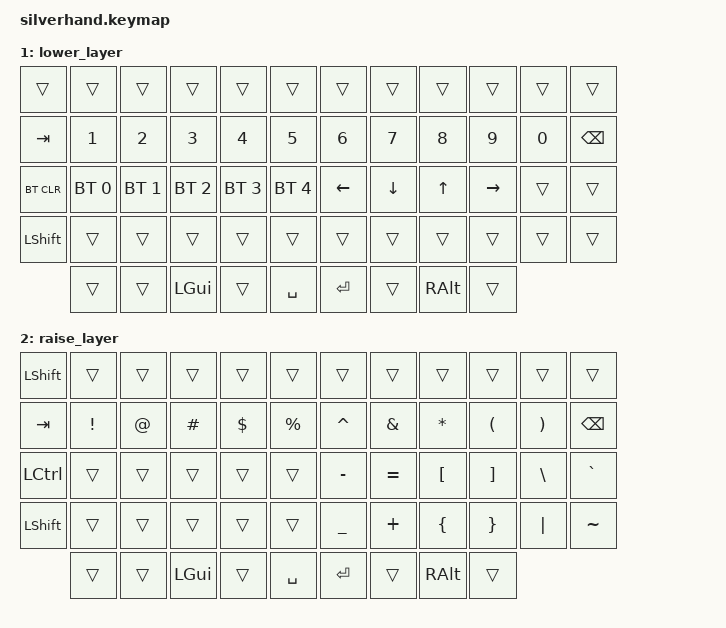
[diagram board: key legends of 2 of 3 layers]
#include <behaviors.dtsi>
#include <dt-bindings/zmk/keys.h>
#include <dt-bindings/zmk/bt.h>

/ {
        keymap {
                compatible = "zmk,keymap";

                default_layer {
// -----------------------------------------------------------------------------------------
// |  ESC |  1   |  2  |  3  |  4  |  5  |   |  6  |  7   |  8  |  9  |  0  |   -  |
// |  TAB |  Q   |  W  |  E  |  R  |  T  |   |  Y  |  U   |  I  |  O  |  P  | BSPC |
// | Caps |  A   |  S  |  D  |  F  |  G  |   |  H  |  J   |  K  |  L  |  ;  |  '   |
// | SHFT |  Z   |  X  |  C  |  V  |  B  |   |  N  |  M   |  ,  |  .  |  /  | ESC  |
//        | CTRL | ALT | GUI | LWR | SPC |         | ENT | RSE  | ALT |
                        bindings = <
   &kp ESC    &kp N1   &kp N2   &kp N3   &kp N4  &kp N5       &kp N6   &kp N7  &kp N8     &kp N9    &kp N0    &kp MINUS
   &kp TAB    &kp Q    &kp W    &kp E    &kp R   &kp T        &kp Y    &kp U   &kp I      &kp O     &kp P     &kp BSPC
   &kp CAPS   &kp A    &kp S    &kp D    &kp F   &kp G        &kp H    &kp J   &kp K      &kp L     &kp SEMI  &kp SQT
   &kp LSHFT  &kp Z    &kp X    &kp C    &kp V   &kp B        &kp N    &kp M   &kp COMMA  &kp DOT   &kp FSLH  &kp ESC
              &kp LCTRL &kp LALT &kp LGUI &mo 1   &kp SPACE    &kp RET  &mo 2   &kp RALT   &kp LCTRL  &trans
                        >;
                };
                lower_layer {
// -----------------------------------------------------------------------------------------
// |  TAB |  1  |  2  |  3  |  4  |  5  |   |  6  |  7  |  8  |  9  |  0  | BSPC |
// | BTCLR| BT1 | BT2 | BT3 | BT4 | BT5 |   | LFT | DWN |  UP | RGT |     |      |
// | SHFT |     |     |     |     |     |   |     |     |     |     |     |      |
//                    | GUI |     | SPC |   | ENT |     | ALT |
                        bindings = <
   &trans     &trans       &trans       &trans       &trans       &trans         &trans   &trans   &trans   &trans       &trans &trans
   &kp TAB    &kp N1       &kp N2       &kp N3       &kp N4       &kp N5         &kp N6   &kp N7   &kp N8   &kp N9       &kp N0 &kp BSPC
   &bt BT_CLR &bt BT_SEL 0 &bt BT_SEL 1 &bt BT_SEL 2 &bt BT_SEL 3 &bt BT_SEL 4   &kp LEFT &kp DOWN &kp UP   &kp RIGHT    &trans &trans
   &kp LSHFT  &trans       &trans       &trans       &trans       &trans         &trans   &trans   &trans   &trans       &trans &trans
              &trans       &trans       &kp LGUI     &trans       &kp SPACE      &kp RET  &trans   &kp RALT &trans       
                        >;
                };

                raise_layer {
// -----------------------------------------------------------------------------------------
// |  TAB |  !  |  @  |  #  |  $  |  %  |   |  ^  |  &  |  *  |  (  |  )  | BSPC |
// | CTRL |     |     |     |     |     |   |  -  |  =  |  [  |  ]  |  \  |  `   |
// | SHFT |     |     |     |     |     |   |  _  |  +  |  {  |  }  | "|" |  ~   |
//                    | GUI |     | SPC |   | ENT |     | ALT |
                        bindings = <
   &kp LSHFT  &trans     &trans       &trans       &trans      &trans      &trans    &trans   &trans &trans    &trans &trans
   &kp  TAB   &kp EXCL   &kp AT  &kp HASH &kp DLLR &kp PRCNT   &kp CARET   &kp AMPS  &kp ASTRK &kp LPAR &kp RPAR &kp BSPC
   &kp LCTRL  &trans     &trans  &trans   &trans   &trans      &kp MINUS   &kp EQUAL &kp LBKT  &kp RBKT &kp BSLH &kp GRAVE
   &kp LSHFT  &trans     &trans  &trans   &trans   &trans      &kp UNDER   &kp PLUS  &kp LBRC  &kp RBRC &kp PIPE &kp TILDE
              &trans     &trans  &kp LGUI &trans   &kp SPACE   &kp RET     &trans    &kp RALT  &trans 
                        >;
                };
        };
};
